# AT32UC3C0128C device description
Architecture: AVR32_UC3; Family: AVR UC3
Registers are 32-bit, read-write, reset 0x0 unless marked. A register's access mark holds for its fields unless they carry their own. Offsets are from the block's base; [hi:lo] are bit positions; lines under a group give offsets from that group; {n}, {i} and the like mark numbered series; 'fields as' and 'values as' point back to an identical list; <NAME> marks a mode.

## TC — Timer/Counter
Instances: TC0 0xfffd2000, TC1 0xffff5800
{0x0+0x40*i} channel[{i}] (i=0..2) group
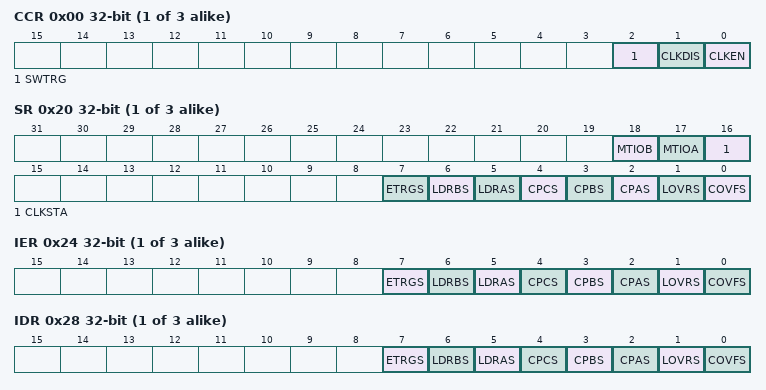
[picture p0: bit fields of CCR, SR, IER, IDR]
  0x00 CCR wo — Channel Control Register Channel 0
    [2] SWTRG — Software Trigger Command
    [1] CLKDIS — Counter Clock Disable Command
    [0] CLKEN — Counter Clock Enable Command
  0x04 CMR — Channel Mode Register Channel 0
    [19:18] LDRB <capture> — RB Loading Selection
      0=NO_EDGE; 1=POS_EDGE_TIOA; 2=NEG_EDGE_TIOA; 3=BIOTH_EDGES_TIOA
    [17:16] LDRA <capture> — RA Loading Selection
      values as LDRB<capture>
    [15] WAVE <capture>
    [14] CPCTRG <capture> — RC Compare Trigger Enable
    [10] ABETRG <capture> — TIOA or TIOB External Trigger Selection
    [9:8] ETRGEDG <capture> — External Trigger Edge Selection
      0=NO_EDGE; 1=POS_EDGE; 2=NEG_EDGE; 3=BOTH_EDGES
    [7] LDBDIS <capture> — Counter Clock Disable with RB Loading
    [6] LDBSTOP <capture> — Counter Clock Stopped with RB Loading
    [5:4] BURST <capture> — Burst Signal Selection
      0=NOT_GATED; 1=CLK_AND_XC0; 2=CLK_AND_XC1; 3=CLK_AND_XC2
    [3] CLKI <capture> — Clock Invert
    [2:0] TCCLKS <capture> — Clock Selection
      {v}=TIMER_DIV{v+1}_CLOCK (v=0..4); 5=XC0; 6=XC1; 7=XC2
    [31:30] BSWTRG <waveform> — Software Trigger Effect on TIOB
      0=NONE; 1=SET; 2=CLEAR; 3=TOGGLE
    [29:28] BEEVT <waveform> — External Event Effect on TIOB
      0=NONE; 1=SET; 2=CLEAR; 3=TOGGLE
    [27:26] BCPC <waveform> — RC Compare Effect on TIOB
      0=NONE; 1=SET; 2=CLEAR; 3=TOGGLE
    [25:24] BCPB <waveform> — RB Compare Effect on TIOB
      0=NONE; 1=SET; 2=CLEAR; 3=TOGGLE
    [23:22] ASWTRG <waveform> — Software Trigger Effect on TIOA
      0=NONE; 1=SET; 2=CLEAR; 3=TOGGLE
    [21:20] AEEVT <waveform> — External Event Effect on TIOA
      0=NONE; 1=SET; 2=CLEAR; 3=TOGGLE
    [19:18] ACPC <waveform> — RC Compare Effect on TIOA
      0=NONE; 1=SET; 2=CLEAR; 3=TOGGLE
    [17:16] ACPA <waveform> — RA Compare Effect on TIOA
      0=NONE; 1=SET; 2=CLEAR; 3=TOGGLE
    [15] WAVE <waveform>
    [14:13] WAVSEL <waveform> — Waveform Selection
      0=UP_NO_AUTO; 1=UPDOWN_NO_AUTO; 2=UP_AUTO; 3=UPDOWN_AUTO
    [12] ENETRG <waveform> — External Event Trigger Enable
    [11:10] EEVT <waveform> — External Event Selection
      0=TIOB_INPUT; 1=XC0_OUTPUT; 2=XC1_OUTPUT; 3=XC2_OUTPUT
    [9:8] EEVTEDG <waveform> — External Event Edge Selection
      0=NO_EDGE; 1=POS_EDGE; 2=NEG_EDGE; 3=BOTH_EDGES
    [7] CPCDIS <waveform> — Counter Clock Disable with RC Compare
    [6] CPCSTOP <waveform> — Counter Clock Stopped with RC Compare
    [5:4] BURST <waveform> — Burst Signal Selection
      0=NOT_GATED; 1=CLK_AND_XC0; 2=CLK_AND_XC1; 3=CLK_AND_XC2
    [3] CLKI <waveform> — Clock Invert
    [2:0] TCCLKS <waveform> — Clock Selection
      {v}=TIMER_DIV{v+1}_CLOCK (v=0..4); 5=XC0; 6=XC1; 7=XC2
  0x10 CV ro — Counter Value Channel 0
    [15:0] CV — Counter Value
  0x14 RA — Register A Channel 0
    [15:0] RA — Register A
  0x18 RB — Register B Channel 0
    [15:0] RB — Register B
  0x1C RC — Register C Channel 0
    [15:0] RC — Register C
  0x20 SR ro — Status Register Channel 0
    [18] MTIOB — TIOB Mirror
    [17] MTIOA — TIOA Mirror
    [16] CLKSTA — Clock Enabling Status
    [7] ETRGS — External Trigger Status
    [6] LDRBS — RB Loading Status
    [5] LDRAS — RA Loading Status
    [4] CPCS — RC Compare Status
    [3] CPBS — RB Compare Status
    [2] CPAS — RA Compare Status
    [1] LOVRS — Load Overrun Status
    [0] COVFS — Counter Overflow Status
  0x24 IER wo — Interrupt Enable Register Channel 0
    [7] ETRGS — External Trigger
    [6] LDRBS — RB Loading
    [5] LDRAS — RA Loading
    [4] CPCS — RC Compare
    [3] CPBS — RB Compare
    [2] CPAS — RA Compare
    [1] LOVRS — Load Overrun
    [0] COVFS — Counter Overflow
  0x28 IDR wo — Interrupt Disable Register Channel 0
    fields as channel[0].IER
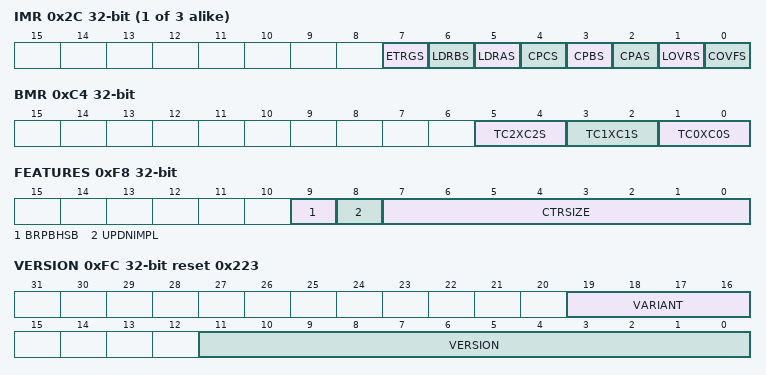
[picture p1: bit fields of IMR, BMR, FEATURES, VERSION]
  0x2C IMR ro — Interrupt Mask Register Channel 0
    fields as channel[0].IER
0xC0 BCR wo — TC Block Control Register
  [0] SYNC — Synchro Command
0xC4 BMR — TC Block Mode Register
  [5:4] TC2XC2S — External Clock Signal 2 Selection
    0=TCLK2; 1=NO_CLK; 2=TIOA0; 3=TIOA1
  [3:2] TC1XC1S — External Clock Signal 1 Selection
    0=TCLK1; 1=NO_CLK; 2=TIOA0; 3=TIOA2
  [1:0] TC0XC0S — External Clock Signal 0 Selection
    0=TCLK0; 1=NO_CLK; 2=TIOA1; 3=TIOA2
0xF8 FEATURES ro reset not defined
  [9] BRPBHSB — Bridge Type is PB to HSB
  [8] UPDNIMPL — Up Down is Implemented
  [7:0] CTRSIZE — Counter Size
0xFC VERSION ro reset 0x223
  [19:16] VARIANT — Reserved. Value subject to change. No functionality associated.
  [11:0] VERSION — Reserved. Value subject to change. No functionality associated. This is the Atmel internal version of the macrocell.
